# PIC32CM5112SG00048 register map
Vendor: Microchip Technology; Series: PIC32CMSG00; File version: 0
CPU: CM23 r0p0, little endian, MPU, no FPU, 2 interrupt priority bits, 141 interrupts, 13 SAU regions
Registers are 32-bit, read-write, reset 0x0 unless marked. A register's access mark holds for its fields unless they carry their own. Offsets are from the block's base; [hi:lo] are bit positions; 'fields as' and 'values as' point back to an identical list.

## FCR — Polaris Flash Read Controller
Base 0x44002000
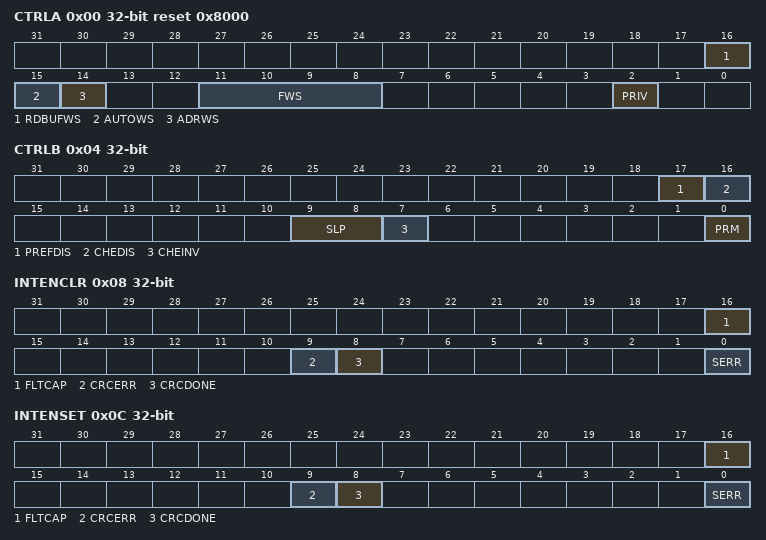
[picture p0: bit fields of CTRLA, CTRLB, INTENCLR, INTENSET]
0x00 CTRLA reset 0x8000
  [16] RDBUFWS — Read Buffer Wait StatesPer AHB port control of deterministic or zero wait state read buffer access.
    0=ZEROWS (0 Wait States); 1=DETERMINISTIC (ADRWS + FWS wait state for hits to AHB read buffer)
  [15] AUTOWS — Automatic Wait State Enable.
    0=DISABLE (Use FWS: Total flash wait states are ADRWS + FWS); 1=ENABLE (Use Automatic wait states: Total flash wait states are ADRWS + Taws)
  [14] ADRWS — Address Wait State Enable
    0=ZERO (Add 0 Address Wait States - allowing for higher performance at lower clock frequencies); 1=ONE (Add 1 Address Wait State - allowing for higher clock frequencies)
  [11:8] FWS — Flash Access Time Defined in terms of AHB Clock Wait States
    0=Zero Wait States; 1=One Wait State; 14=Fourteen Wait States; 15=Fifteen Wait States
  [2] PRIV — Privileged Access Only
    0=DISABLE (Macro register accessible in privileged and unprivileged accesses.); 1=ENABLE (Macro registers only accessible in privileged accesses)
0x04 CTRLB
  [17] PREFDIS — Prefetch Disable
    0=ENABLE (Predictive Prefetch Enabled); 1=DISABLE (Predictive Prefetch Disabled)
  [16] CHEDIS — Cache Disable
    0=ENABLE (Cache Enabled; Accesses to flash use AUTOWS/FSW selection.); 1=DISABLE (Cache Disabled; Interface uses RDBUFWS selection.)
  [9:8] SLP — NVM Power Reduction Mode selection during System Standby Sleep
    0=MANUAL (Maintain state of STATUS.PRM on entry to Standby); 2=AUTOFAST (Enter Flash Hibernate on entry to Standby w/ wakeup to Auto Standby); 3=AUTOSLOW (Enter Flash Hibernate on entry to Standby w/ wakeup on first access)
  [7] CHEINV — Cache InvalidateCache invalidation takes 1 clock cycle, but may be delayed by an active read.
    0=NONE (No Action); 1=INV (Invalidate Cache)
  [0] PRM — Set NVM Power Reduction Mode
    0=NONE (No Action); 1=TOGGLE (Toggle the Flash Power Mode)
0x08 INTENCLR write-1-clears — Interrupt Enable Clear REGISTER
  [all] fields
    0=Interrupt Disabled; 1=Interrupt Enabled
  [16] FLTCAP — ECC Fault Capture Clear Enable
  [9] CRCERR — CRC Error Clear Enable
  [8] CRCDONE — CRC Calculation Done Clear Enable
  [0] SERR — Flash SEC Interrupt Clear Enable
0x0C INTENSET write-1-sets — Interrupt Enable SET REGISTER
  [all] fields
    0=Interrupt Disabled; 1=Interrupt Enabled
  [16] FLTCAP — ECC Fault Capture Set Enable
  [9] CRCERR — CRC Error Set Enable
  [8] CRCDONE — CRC Calculation Done Set Enable
  [0] SERR — Flash SEC Interrupt Set Enable
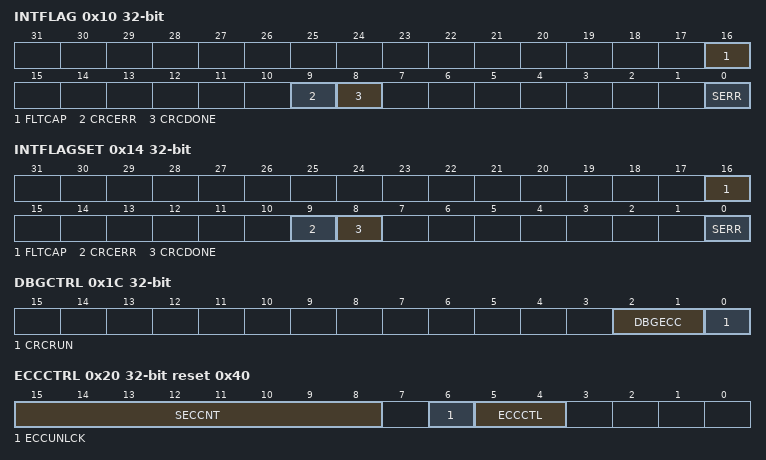
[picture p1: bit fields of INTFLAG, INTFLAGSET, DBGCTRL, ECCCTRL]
0x10 INTFLAG write-1-clears — Interrupt Flag REGISTER
  [16] FLTCAP — ECC Fault Capture Flag
    0=No Interrupt Pending; 1=An ECC Fault Capture, related to FLTMD[], occurred
  [9] CRCERR — CRC Error Flag
    0=No Interrupt Pending; 1=CRCACC Is Not Equal to the XOR of CRCSUM and CRCFXOR
  [8] CRCDONE — CRC Calculation Done Flag
    0=No Interrupt Pending; 1=Calculation Done
  [0] SERR — Flash SEC Interrupt Flag
    0=No Interrupt Pending; 1=SECCNT Count reached
0x14 INTFLAGSET write-1-clears — Interrupt Flag Set REGISTER
  [16] FLTCAP — ECC Fault Capture Flag
    0=No effect; 1=Set Interrupt Pending
  [9] CRCERR — CRC Error Flag
    0=No effect; 1=Set Interrupt Pending
  [8] CRCDONE — CRC Calculation Done Flag
    0=No effect; 1=Set Interrupt Pending
  [0] SERR — Flash SEC Interrupt Flag
    0=No Interrupt Pending; 1=SECCNT Count reached
0x18 STATUS ro reset 0xE0000000
  [0] PRM — NVM Power Reduction Mode Status
    0=Flash is Ready (for read or NVMOP); 1=Flash is Powered Down and wakes on first access (read or NVMOP)
0x1C DBGCTRL — Debug Control CTRL REGISTER
  [2:1] DBGECC — Debug ECC ModeECC errors from debugger reads are:
    0=NOERR (Corrected per ECCCTRL; No Bus ERR; INTFLAG, SEC counter, and FLT logic are not updated.); 1=DISABLE (Not corrected; No Bus Error; INTFLAG, SEC counter, and FLT logic are not updated.); 2=ENABLE (Corrected per ECCCTRL; Bus Error, INTFLAG, SEC counter, and FLT logic operates as setup.); 3=RSVD11 (Don't use but same as 01 (DISABLE))
  [0] CRCRUN — CRC Debug Run Enable
    0=HALT (CRC Logic Halts in Debug Mode); 1=RUN (CRC Logic Runs in Debug Mode.)
0x20 ECCCTRL reset 0x40 — ECC Control REGISTER
  [15:8] SECCNT — Flash SEC Count
  [6] ECCUNLCK — NVM ECC Mode Control Unlock
    0=LOCKED (ECCUNLCK and ECCCTL[1:0] cannot be written); 1=UNLOCKED (ECCUNLCK and ECCCTL[1:0] can be written)
  [5:4] ECCCTL — NVM ECC Mode Control - restricts one or more NVMOPs
    0=STRICT (ECC Writes with ECC Reads (NVMOP = Single Program Operation disabled)); 1=DYNAMIC (Dynamic Writes with Dynamic Reads); 2=ECC (ECC Writes with Dynamic Reads (NVMOP = Single Program Operation disabled)); 3=DISABLE (Dynamic Writes with No Error Check Reads)
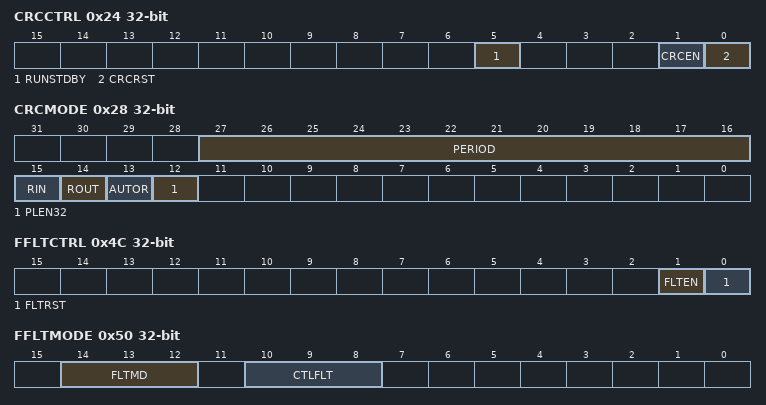
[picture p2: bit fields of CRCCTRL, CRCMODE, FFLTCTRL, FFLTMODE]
0x24 CRCCTRL — CRC Control REGISTER
  [5] RUNSTDBY — CRC Run in Standby
    0=HALT (CRC Halts in Standby); 1=RUN (CRC Runs in Standby but only if STATUS.PRM=0 (i.e. Flash is in Auto Standby))
  [1] CRCEN — Start CRC Calculation
    0=DISABLE (Stops CRC calculation.); 1=ENABLE (CRC Calculation Enabled (w/ start on write to 1).)
  [0] CRCRST — CRC Reset
    0=NONE (No Action); 1=RESET (Resets all CRC SFR bits.)
0x28 CRCMODE
  [27:16] PERIOD — Read Period in PerCLK counts
  [15] RIN — CRC Reflected Input
    0=DISABLE (The LFSR CRC is calculated Most Significant Bit first (Not Reflected)); 1=ENABLE (The LFSR CRC is calculated Least Significant Bit first (Reflected))
  [14] ROUT — CRC Reflected Output
    0=DISABLE (The CRCACC is Not Reflected); 1=ENABLE (The CRCACC is Reflected (before the Final XOR))
  [13] AUTOR — CRC Auto Repeat
    0=DISABLE (Perform CRC calculation once then set DONE and if needed, CRCERR.); 1=ENABLE (Continually Repeat CRC calculation; stop on error, set CRCDONE and CRCERR)
  [12] PLEN32 — Polynomial Length Select
    0=SIXTEEN (Polynomial is 16-bits); 1=THIRTYTWO (Polynomial is 32-bits)
0x2C CRCPAUSE
  [0] PAUSE — CRC Pause
    0=DISABLE (CRC Reads Flash as Required); 1=ENABLE (Pause CRC Reads of Flash)
0x30 CRCMADR — CRC Message Address REGISTER
  [27:0] CRCMADR — Message Start Address in Flash
0x34 CRCMLEN — CRC Message Length REGISTER
  [19:0] CRCMLEN — Message Length in Bytes
0x38 CRCIV — CRC Initial Value REGISTER
  [31:0] CRCIV — CRC Initial Value
0x3C CRCACC ro — CRC Accumulator REGISTER
  [31:0] CRCACC — CRC Accumulator Result
0x40 CRCPOLY reset 0x1 — CRC Polynomial REGISTER
  [31:0] CRCPOLY — CRC Polynomial Coefficients for LFSR
    0=Disable the XOR input to the shift register at the associated bit position; 1=Enable the XOR input to the shift register at the associated bit position
0x44 CRCFXOR — CRC Final XOR REGISTER
  [31:0] CRCFXOR — CRC Final XOR
    0=Disable the Final XOR at the associated bit position; 1=Enable the Final XOR at the associated bit position
0x48 CRCSUM — CRC CheckSUM REGISTER
  [31:0] CRCSUM — CRC Checksum
0x4C FFLTCTRL — Flash ECC Fault Control REGISTER
  [1] FLTEN — ECC Fault Enable bit
    0=DISABLE (ECC Fault Injection Disabled); 1=ENABLE (ECC Fault Injection Enabled (module performs operation selected by FFLTMODE.FLTMD))
  [0] FLTRST — Fault Reset
    0=NONE (No Action); 1=RESET (Resets all FLT SFR bits.)
0x50 FFLTMODE — Flash ECC Fault Mode REGISTER
  [14:12] FLTMD — Fault Mode Control
    0=DISABLE (Fault Injection Disabled); 2=CAPT (Fault Capture Mode Enabled - Captures the address (in FLTADR) and Syndrome in (FLTSYN)); 4=SINGLEREAD (Single Fault Injection (at bit selected by FLT1PTR) for Reads); 5=DOUBLEREAD (Double Fault Injection for Reads); 6=SINGLEWRITE (Single Fault Injection (at bit selected by FLT1PTR) for Writes); 7=DOUBLEWRITE (Double Fault Injection for Writes)
  [10:8] CTLFLT — ECC/Parity Control Fault bits
    0=No Fault Injected; 1=Inject a Fault on to the associated ECC/Parity Control bits (CTL[n])
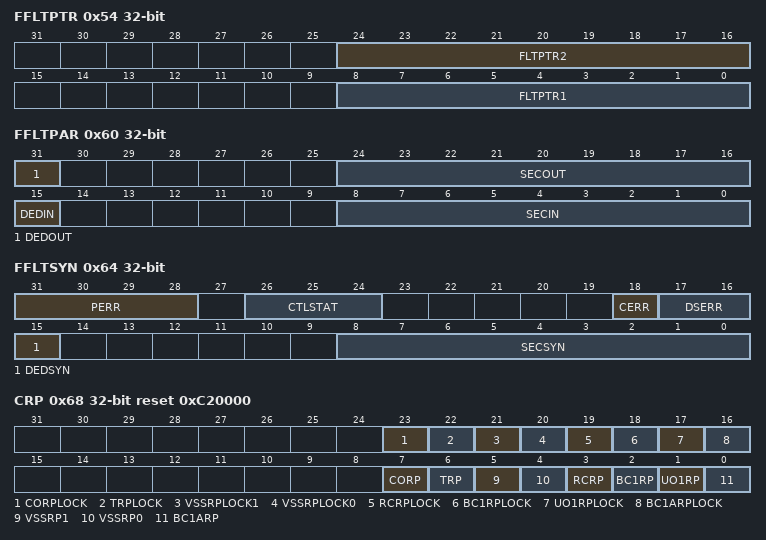
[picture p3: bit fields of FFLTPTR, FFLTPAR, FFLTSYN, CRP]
0x54 FFLTPTR — Flash ECC Fault Pointer REGISTER
  [24:16] FLTPTR2 — Fault 2 Injection Pointer
  [8:0] FLTPTR1 — Fault 1 Injection Pointer
0x58 FFLTADR — Flash ECC Fault Address REGISTER
  [27:0] FLTADR — Fault Injection Address
0x5C FFLTCAP ro — Flash ECC Fault Capture Address REGISTER
  [27:0] FLTADR — Fault Capture Address
0x60 FFLTPAR ro — Flash ECC Fault Parity REGISTER
  [31] DEDOUT — The Calculated Overall Parity used in Double Error Detection
  [24:16] SECOUT — The Calculated Single Error Parity bits
  [15] DEDIN — The Overall Parity from Flash
  [8:0] SECIN — The Single Error Parity bits from Flash
0x64 FFLTSYN ro — Flash ECC Fault Syndrome REGISTER
  [31:28] PERR — Per Word (n=3:0) Parity Error Status
    0=NONE (No Parity Error on Word n); 1=ERROR (Parity Error on Word n)
  [26:24] CTLSTAT — Parity vs ECC Control Status
    0=USEDECC_0 (Calculation used ECC (i.e. programming used quad write)); 1=USEDECC_1 (Calculation used ECC (i.e. programming used quad write)); 2=USEDECC_10 (Calculation used ECC (i.e. programming used quad write)); 3=USEDPARITY_11 (Calculation used Parity (i.e. programming used single write)); 4=USEDECC_100 (Calculation used ECC (i.e. programming used quad write)); 5=USEDPARITY_101 (Calculation used Parity (i.e. programming used single write)); 6=USEDPARITY_110 (Calculation used Parity (i.e. programming used single write)); 7=USEDPARITY_111 (Calculation used Parity (i.e. programming used single write))
  [18] CERR — ECC Control bit Error
    0=NONE (No Control bit Error (ECCSTAT either 111 or 000)); 1=SINGLE (Single Control Bit Error)
  [17:16] DSERR — Double Error Detected & Single Error Corrected
    0=NONE (No Errors); 1=SINGLE (Single Error Corrected); 2=DOUBLE_10 (Double Error Detected); 3=DOUBLE_11 (Double Error Detected)
  [15] DEDSYN — DED Syndrome
    0=Calculated Overall Parity Concurs with Read Overall Parity; 1=Calculated Overall Parity Differs from Read Overall Parity
  [8:0] SECSYN — Single Error Correction Syndrome
0x68 CRP reset 0xC20000 — CFM Page Read Protection REGISTER (CFM8)
  [23] CORPLOCK — Panel 1 Lock Read Protection CalOTP
    1=LOCKED (The Lock & Read Protect bits for this Page are Locked and cannot be modified)
  [22] TRPLOCK — Panel 1 Lock Read Protection Test
    values as CORPLOCK
  [21] VSSRPLOCK1 — Panel 1 Lock Read Protection VSSn
    0=UNLOCKED (The Lock & Read Protect bits for this Page are NOT Locked and can be modified); 1=LOCKED (The Lock & Read Protect bits for this Page are Locked and cannot be modified)
  [20] VSSRPLOCK0 — Panel 1 Lock Read Protection VSSn
    values as VSSRPLOCK1
  [19] RCRPLOCK — Panel 1 Lock Read Protection ROMCfg
    values as VSSRPLOCK1
  [18] BC1RPLOCK — Panel 1 Lock Read Protection BootCfg1
    values as VSSRPLOCK1
  [17] UO1RPLOCK — Panel 1 Lock Read Protection UserOTP1
    values as CORPLOCK
  [16] BC1ARPLOCK — Panel 1 Lock Read Protection BootCfg1A
    values as VSSRPLOCK1
  [7] CORP — Panel 1 Read Protect CalOTP
    0=DISABLE (Read Protection for this Page is Disabled); 1=ENABLE (Read Protection for this Page is Enabled)
  [6] TRP — Panel 1 Read Protect Test
    values as CORP
  [5] VSSRP1 — Panel 1 Read Protect VSSn
    values as CORP
  [4] VSSRP0 — Panel 1 Read Protect VSSn
    values as CORP
  [3] RCRP — Panel 1 Read Protect ROMCfg
    values as CORP
  [2] BC1RP — Panel 1 Read Protect BootCfg1
    values as CORP
  [1] UO1RP — Panel 1 Read Protect UserOTP1
    0=DISABLE (Read Protection for this Page is Disabled)
  [0] BC1ARP — Panel 1 Read Protect BootCfg1A
    values as CORP
